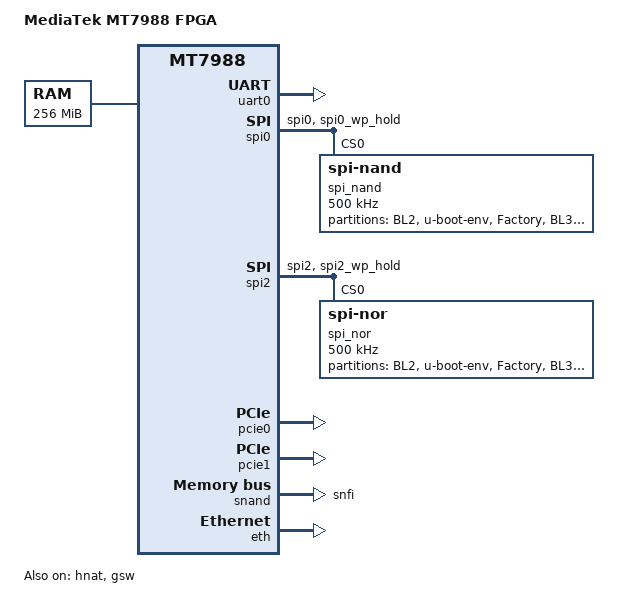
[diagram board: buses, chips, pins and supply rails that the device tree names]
/dts-v1/;
#include "mt7988-fpga.dtsi"
/ {
	model = "MediaTek MT7988 FPGA";
	compatible = "mediatek,mt7988-fpga";
	chosen {
		bootargs = "console=ttyS0,115200n1 loglevel=8  \
				earlycon=uart8250,mmio32,0x11000000";
	};

	memory {
		// fpga ddr2: 128MB*2
		reg = <0 0x40000000 0 0x10000000>;
	};

		gsw: gsw@0 {
				compatible = "mediatek,mt753x";
				mediatek,ethsys = <&ethsys>;
				reg = <0 0x15020000 0 0x8000>;
				#address-cells = <1>;
				#size-cells = <0>;
		};
        wsys_adie: wsys_adie@0 {
		// fpga cases need to manual change adie_id / sku_type for dvt only
                compatible = "mediatek,rebb-mt7981-adie";
                adie_id = <7976>;
                sku_type = <3000>;
        };
};

&uart0 {
	status = "okay";
};

&spi0 {
	pinctrl-names = "default";
	pinctrl-0 = <&spi0_flash_pins>;
	status = "okay";
	spi_nand@0 {
		#address-cells = <1>;
		#size-cells = <1>;
		compatible = "spi-nand";
		reg = <0>;
		spi-max-frequency = <500000>;

		partition@00000 {
			label = "BL2";
			reg = <0x00000 0x0100000>;
		};
		partition@100000 {
			label = "u-boot-env";
			reg = <0x100000 0x0080000>;
		};
		partition@180000 {
			label = "Factory";
			reg = <0x180000 0x00200000>;
		};
		partition@380000 {
			label = "BL31";
			reg = <0x380000 0x0080000>;
		};
		partition@400000 {
			label = "u-boot";
			reg = <0x400000 0x0180000>;
		};
		partition@580000 {
			label = "firmware";
			reg = <0x580000 0x7a80000>;
		};
	};
};

&spi1 {
	pinctrl-names = "default";
	/* pin shared with snfi */
	pinctrl-0 = <&spic_pins>;
	status = "disabled";
};

&spi2 {
	pinctrl-names = "default";
	pinctrl-0 = <&spi2_flash_pins>;
	status = "okay";
	spi_nor@0 {
		#address-cells = <1>;
		#size-cells = <1>;
		compatible = "jedec,spi-nor";
		reg = <0>;
		spi-max-frequency = <500000>;

		partition@00000 {
			label = "BL2";
			reg = <0x00000 0x0060000>;
		};
		partition@60000 {
			label = "u-boot-env";
			reg = <0x60000 0x0010000>;
		};
		partition@70000 {
			label = "Factory";
			reg = <0x70000 0x00B0000>;
		};
		partition@120000 {
			label = "BL31";
			reg = <0x120000 0x0010000>;
		};
		partition@130000 {
			label = "u-boot";
			reg = <0x130000 0x00D0000>;
		};
		partition@200000 {
			label = "firmware";
			reg = <0x200000 0xE00000>;
		};
	};
};

&pcie0 {
	status = "okay";
};

&pcie1 {
	status = "okay";
};

&pio {
	pcie_pins: pcie-pins {
		mux {
			function = "pcie";
			groups = "pcie_pereset", "pcie_clk", "pcie_wake";
		};
	};

	spi0_flash_pins: spi0-pins {
		mux {
			function = "spi";
			groups = "spi0", "spi0_wp_hold";
		};
	};

	snfi_pins: snfi-pins {
		mux {
			function = "flash";
			groups = "snfi";
		};
	};

	spic_pins: spi1-pins {
		mux {
			function = "spi";
			groups = "spi1_1";
		};
	};

	spi2_flash_pins: spi2-pins {
		mux {
			function = "spi";
			groups = "spi2", "spi2_wp_hold";
		};
	};
};

&watchdog {
	status = "disabled";
};

&snand {
	pinctrl-names = "default";
	/* pin shared with spic */
	pinctrl-0 = <&snfi_pins>;
	status = "okay";
	mediatek,quad-spi;

	partitions {
		compatible = "fixed-partitions";
		#address-cells = <1>;
		#size-cells = <1>;

		partition@0 {
			label = "BL2";
			reg = <0x00000 0x0080000>;
			read-only;
		};

		partition@80000 {
			label = "FIP";
			reg = <0x80000 0x0200000>;
		};

		partition@280000 {
			label = "u-boot-env";
			reg = <0x280000 0x0080000>;
		};

		partition@300000 {
			label = "Factory";
			reg = <0x300000 0x0080000>;
		};

		partition@380000 {
			label = "firmware";
			reg = <0x380000 0x7c00000>;
		};
	};
};

&eth {
        status = "okay";

        gmac0: mac@0 {
                compatible = "mediatek,eth-mac";
                reg = <0>;
                phy-mode = "rgmii";

                fixed-link {
                        speed = <100>;
                        full-duplex;
                        pause;
                };
        }; 
	gmac1: mac@1 {
                compatible = "mediatek,eth-mac";
                reg = <1>;
                phy-mode = "rgmii";

                fixed-link {
                        speed = <100>;
                        full-duplex;
                        pause;
                };
        };

        mdio: mdio-bus {
                #address-cells = <1>;
                #size-cells = <0>;
        };

}; 

&hnat {
	mtketh-wan = "eth1";
	mtketh-lan = "eth0";
	mtketh-max-gmac = <2>;
	status = "okay";
};

&gsw {
		mediatek,mdio = <&mdio>;
		mediatek,portmap = "llllw";
		mediatek,mdio_master_pinmux = <1>;
		reset-gpios = <&pio 5 0>; 
		interrupt-parent = <&pio>;
		interrupts = <66 IRQ_TYPE_LEVEL_HIGH>;
		status = "okay";

		port6: port@6 {
				compatible = "mediatek,mt753x-port";
				mediatek,ssc-on;
				reg = <6>;
				phy-mode = "sgmii";
				fixed-link {
						speed = <2500>;
						full-duplex;
				};
		};
};
